# PIC32MX430F064L device description
Architecture: MIPS; Family: PIC32MX; Series: PIC32MX
Registers are 32-bit, read-write, no defined reset value unless marked. A register's access mark holds for its fields unless they carry their own. Offsets are from the block's base; [hi:lo] are bit positions; {n}, {i} and the like mark numbered series.

## PCACHE
Instances: PCACHE 0x1f884000 in periph2
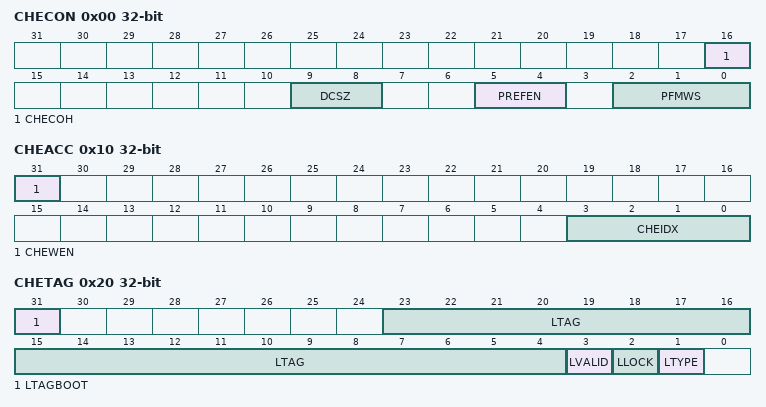
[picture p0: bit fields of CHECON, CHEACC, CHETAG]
0x00 CHECON — Cache Control Register
  [16] CHECOH — Cache Coherency Setting on a PFM Program Cycle bit
    1=Invalidate all data and instruction lines; 0=Invalidate all data lines and instruction lines that are not locked
  [9:8] DCSZ — Data Cache Size in Lines bits
    3=Enable data caching with a size of 4 Lines; 2=Enable data caching with a size of 2 Lines; 1=Enable data caching with a size of 1 Line; 0=Disable data caching
  [5:4] PREFEN — Predictive Prefetch Enable bits
    3=Enable predictive prefetch for both cacheable and non-cacheable regions; 2=Enable predictive prefetch for non-cacheable regions only; 1=Enable predictive prefetch for cacheable regions only; 0=Disable predictive prefetch
  [2:0] PFMWS — PFM Access Time Defined in Terms of SYSLK Wait States bits
    7=Seven Wait states; 6=Six Wait states; 5=Five Wait states; 4=Four Wait states; 3=Three Wait states; 2=Two Wait states; 1=One Wait state; 0=Zero Wait state
0x10 CHEACC — Cache Access Register
  [31] CHEWEN — Cache Access Enable bits for registers CHETAG
    1=The cache line selected by CHEIDX(3:0) is writeable; 0=The cache line selected by CHEIDX(3:0) is not writeable
  [3:0] CHEIDX — Cache Line Index bits
    {v}=Select cache line {v} for reading or writing (v=0..15)
0x20 CHETAG — Cache TAG Register
  [31] LTAGBOOT — Line TAG Address Boot bit
    1=The line is in the 0x1D000000 (physical) area of memory; 0=The line is in the 0x1FC00000 (physical) area of memory
  [23:4] LTAG
  [3] LVALID — Line Valid bit
    1=The line is valid and is compared to the physical address for hit detection; 0=The line is not valid and is not compared to the physical address for hit detection
  [2] LLOCK — Line Lock bit
    1=The line is locked and will not be replaced; 0=The line is not locked and can be replaced
  [1] LTYPE — Line Type bit
    1=The line caches instruction words; 0=The line caches data words
0x30 CHEMSK — Cache TAG Mask Register
  [15:5] LMASK — Line Mask bits
    1=Enables mask logic to force a match on the corresponding bit position in the LTAG(19:0) bits (CHETAG(23:4)) and the physical address; 0=Only writeable for values of CHEIDX(3:0) bits (CHEACC(3:0)) equal to 0x0A and 0x0B. Disables mask logic.
{0x40+0x10*i} CHEW{i} (i=0..3) — Cache Word {i}
0x80 CHELRU — Cache LRU Register
  [24:0] CHELRU
0x90 CHEHIT ro — Cache Hit Statistics Register
0xA0 CHEMIS ro — Cache Miss Statistics Register
0xC0 CHEPFABT ro — Prefetch Cache Abort Statistics Register

## RPOR
Instances: RPOR 0x1f80fb38 in periph1
0x00 RPA14R — Peripheral Pin Select Output Register
  [3:0] RPA14R
0x04 RPA15R — Peripheral Pin Select Output Register
  [3:0] RPA15R
{0x8+4i} RPB{i}R (i=0..3) — Peripheral Pin Select Output Register
  [3:0] RPB{i}R
{0x8+4i} RPB{i}R (i=5..10) — Peripheral Pin Select Output Register
  [3:0] RPB{i}R
0x40 RPB14R — Peripheral Pin Select Output Register
  [3:0] RPB14R
0x44 RPB15R — Peripheral Pin Select Output Register
  [3:0] RPB15R
{0x48+4i} RPC{i}R (i=1..4) — Peripheral Pin Select Output Register
  [3:0] RPC{i}R
0x7C RPC13R — Peripheral Pin Select Output Register
  [3:0] RPC13R
0x80 RPC14R — Peripheral Pin Select Output Register
  [3:0] RPC14R
{0x88+4i} RPD{i}R (i=0..5) — Peripheral Pin Select Output Register
  [3:0] RPD{i}R
{0x88+4i} RPD{i}R (i=8..12) — Peripheral Pin Select Output Register
  [3:0] RPD{i}R
0xC0 RPD14R — Peripheral Pin Select Output Register
  [3:0] RPD14R
0xC4 RPD15R — Peripheral Pin Select Output Register
  [3:0] RPD15R
0xD4 RPE3R — Peripheral Pin Select Output Register
  [3:0] RPE3R
0xDC RPE5R — Peripheral Pin Select Output Register
  [3:0] RPE5R
0xE8 RPE8R — Peripheral Pin Select Output Register
  [3:0] RPE8R
0xEC RPE9R — Peripheral Pin Select Output Register
  [3:0] RPE9R
{0x108+4i} RPF{i}R (i=0..2) — Peripheral Pin Select Output Register
  [3:0] RPF{i}R
0x118 RPF4R — Peripheral Pin Select Output Register
  [3:0] RPF4R
0x11C RPF5R — Peripheral Pin Select Output Register
  [3:0] RPF5R
0x128 RPF8R — Peripheral Pin Select Output Register
  [3:0] RPF8R
0x138 RPF12R — Peripheral Pin Select Output Register
  [3:0] RPF12R
0x13C RPF13R — Peripheral Pin Select Output Register
  [3:0] RPF13R
0x148 RPG0R — Peripheral Pin Select Output Register
  [3:0] RPG0R
0x14C RPG1R — Peripheral Pin Select Output Register
  [3:0] RPG1R
{0x148+4i} RPG{i}R (i=6..9) — Peripheral Pin Select Output Register
  [3:0] RPG{i}R
